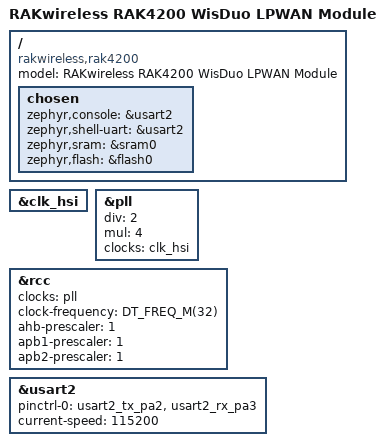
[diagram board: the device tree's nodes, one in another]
/*
 * SPDX-License-Identifier: Apache-2.0
 */

/dts-v1/;
#include <st/l0/stm32l071Xb.dtsi>
#include <st/l0/stm32l071k(b-z)ux-pinctrl.dtsi>

/ {
	model = "RAKwireless RAK4200 WisDuo LPWAN Module";
	compatible = "rakwireless,rak4200";

	chosen {
		zephyr,console = &usart2;
		zephyr,shell-uart = &usart2;
		zephyr,sram = &sram0;
		zephyr,flash = &flash0;
	};
};

&clk_hsi {
	status = "okay";
};

&pll {
	div = <2>;
	mul = <4>;
	clocks = <&clk_hsi>;
	status = "okay";
};

&rcc {
	clocks = <&pll>;
	clock-frequency = <DT_FREQ_M(32)>;
	ahb-prescaler = <1>;
	apb1-prescaler = <1>;
	apb2-prescaler = <1>;
};

&usart2 {
	pinctrl-0 = <&usart2_tx_pa2 &usart2_rx_pa3>;
	pinctrl-names = "default";
	current-speed = <115200>;
	status = "okay";
};
